# rm32 register map
Vendor: Rainer Meng; Series: RM32; File version: 1
CPU: CM0 r0p0, little endian, MPU, no FPU, 4 interrupt priority bits
Registers are 32-bit, read-write, no defined reset value unless marked. A register's access mark holds for its fields unless they carry their own. Offsets are from the block's base; lines under a group give offsets from that group; [hi:lo] are bit positions; {n}, {i} and the like mark numbered series; 'fields as' and 'values as' point back to an identical list; <NAME> marks a mode.

## Memory map
0x40000000 RCC size 0x3FF — Reset and Clock Controller
0x40010000 UART1 size 0x3FF — Universal Synchronous Receiver Transmitter 1
0x40010400 UART2 size 0x3FF — Universal Synchronous Receiver Transmitter 2
0x40010800 TUART1 size 0x3FF — Test Universal Synchronous Receiver Transmitter 1
0x40020000 FMC size 0x3FF — Flash Memory Controller
0x40080000 GPIOA size 0x3FF — General Purpose Input Output A
0x40080400 GPIOB size 0x3FF — General Purpose Input Output B

## FMC — Flash Memory Controller
Base 0x40020000
0x00 ACR — FMC Access Control Register
  [3:0] LATENCY — FMC ACR LATENCY [3:0] Bits: Access latency
0x04 KEYR wo — FMC Key Register
  [31:0] KEY — FMC KEYR KEY [31:0] Bits: Unlock key
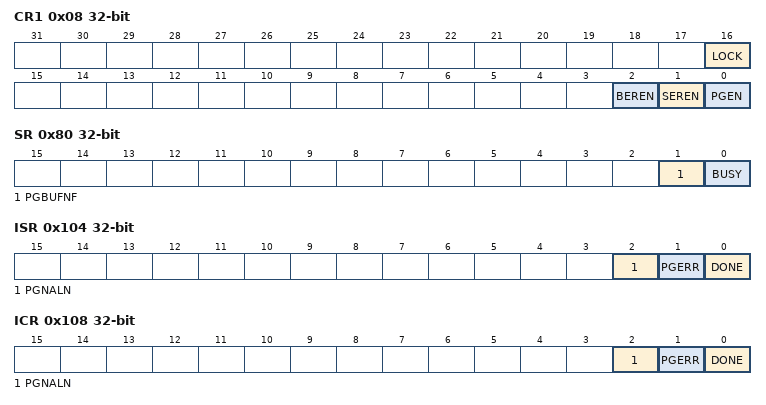
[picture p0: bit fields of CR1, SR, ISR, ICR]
0x08 CR1 — FMC Control Register 1
  [16] LOCK — FMC CR1 LOCK Bit: Lock FMC
  [2] BEREN — FMC CR1 BEREN Bit: Enable / Disable bank erasing
  [1] SEREN — FMC CR1 SEREN Bit: Enable / Disable sector erasing
  [0] PGEN — FMC CR1 PGEN Bit: Enable / Disable programming
0x0C CR2 — FMC Control Register 2
  [0] START — FMC CR2 START Bit: Start erasing
0x40 AR — FMC Address Register
  [31:0] ADDR — FMC AR ADDR [31:0] Bits: Sector erasing address
0x80 SR ro — FMC Status Register
  [1] PGBUFNF — FMC SR PGBUFNF Bit: Programming buf not full
  [0] BUSY — FMC SR BUSY Bit: FMC busy
0x104 ISR ro — FMC Interrupt Status Register
  [2] PGNALN — FMC ISR PGNALN Bit: Programming address not aligned
  [1] PGERR — FMC ISR PGERR Bit: Programming page error
  [0] DONE — FMC ISR DONE Bit: FMC done
0x108 ICR wo — FMC Interrupt Clear Register
  [2] PGNALN — FMC ICR PGNALN Bit: Clear ISR.PGNALN
  [1] PGERR — FMC ICR PGERR Bit: Clear ISR.PGERR
  [0] DONE — FMC ICR DONE Bit: Clear ISR.DONE

## GPIOA — General Purpose Input Output A
Base 0x40080000
Same registers: GPIOB 0x40080400
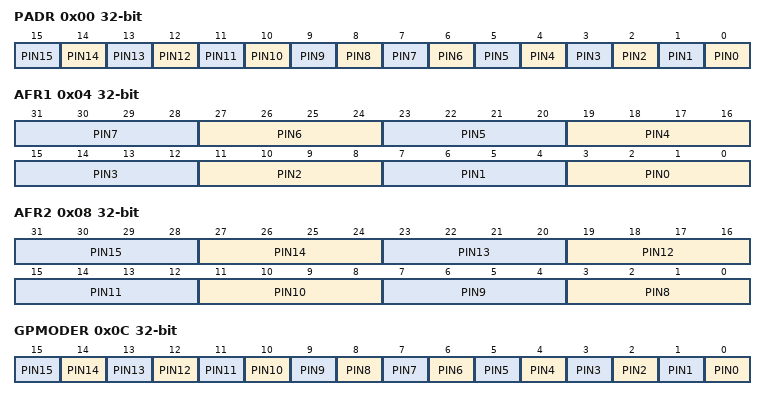
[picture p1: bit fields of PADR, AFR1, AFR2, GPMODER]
0x00 PADR — GPIOA Pad Register
  [n] PIN{n} (n=0..15) — GPIOA PADR PIN{n} Bit: Enable / Disable open drain mode for pin {n}
0x04 AFR1 — GPIOA Alternate Function Register 1
  [4n+3:4n] PIN{n} (n=0..7) — GPIOA AFR1 PIN{n} [3:0] Bits: Alternate function code for pin {n}
0x08 AFR2 — GPIOA Alternate Function Register 2
  [4n-29:4n-32] PIN{n} (n=8..15) — GPIOA AFR2 PIN{n} [3:0] Bits: Alternate function code for pin {n}
0x0C GPMODER — GPIOA Generate Purpose IO Mode Register
  [n] PIN{n} (n=0..15) — GPIOA GPMODER PIN{n} Bit: Select input / output mode for pin {n}
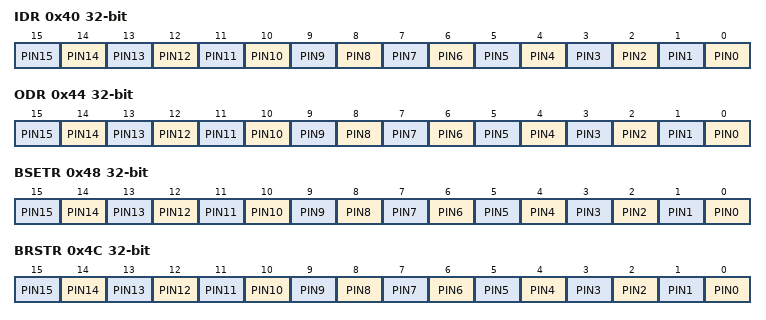
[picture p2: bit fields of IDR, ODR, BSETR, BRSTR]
0x40 IDR ro — GPIOA Input Data Register
  [n] PIN{n} (n=0..15) — GPIOA IDR PIN{n} Bit: Pin {n} input data
0x44 ODR — GPIOA Output Data Register
  [n] PIN{n} (n=0..15) — GPIOA ODR PIN{n} Bit: Pin {n} output data
0x48 BSETR wo — GPIOA Bit Set Register
  [n] PIN{n} (n=0..15) — GPIOA BSETR PIN{n} Bit: Set pin {n}
0x4C BRSTR wo — GPIOA Bit Reset Register
  [n] PIN{n} (n=0..15) — GPIOA BRSTR PIN{n} Bit: Reset pin {n}
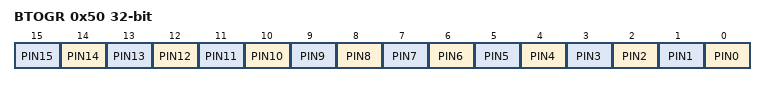
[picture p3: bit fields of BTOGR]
0x50 BTOGR wo — GPIOA Bit Toggle Register
  [n] PIN{n} (n=0..15) — GPIOA BTOGR PIN{n} Bit: Toggle pin {n}

## RCC — Reset and Clock Controller
Base 0x40000000
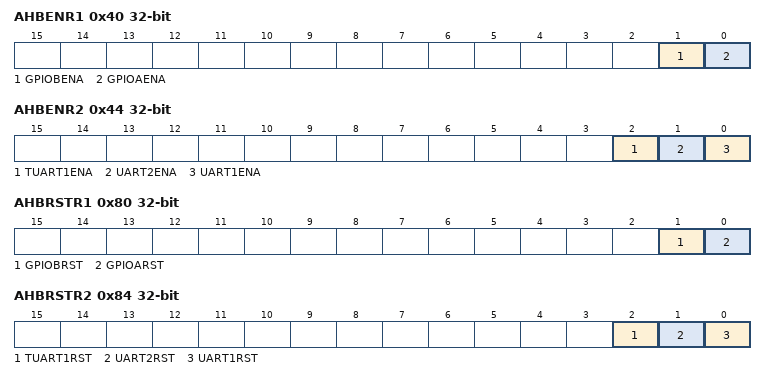
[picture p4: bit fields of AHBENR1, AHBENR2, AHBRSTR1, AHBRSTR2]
0x40 AHBENR1 — RCC AHB Peripheral Enable Register 1
  [1] GPIOBENA — RCC AHBENR1 GPIOBENA Bit: Enable / Disable GPIOB
  [0] GPIOAENA — RCC AHBENR1 GPIOAENA Bit: Enable / Disable GPIOA
0x44 AHBENR2 — RCC AHB Peripheral Enable Register 2
  [2] TUART1ENA — RCC AHBENR2 TUART1ENA Bit: Enable / Disable TUART1
  [1] UART2ENA — RCC AHBENR2 UART2ENA Bit: Enable / Disable UART2
  [0] UART1ENA — RCC AHBENR2 UART1ENA Bit: Enable / Disable UART1
0x80 AHBRSTR1 — RCC AHB Peripheral Reset Register 1
  [1] GPIOBRST — RCC AHBRSTR1 GPIOBRST Bit: Enable / Disable GPIOB
  [0] GPIOARST — RCC AHBRSTR1 GPIOARST Bit: Enable / Disable GPIOA
0x84 AHBRSTR2 — RCC AHB Peripheral Reset Register 2
  [2] TUART1RST — RCC AHBRSTR2 TUART1RST Bit: Enable / Disable TUART1
  [1] UART2RST — RCC AHBRSTR2 UART2RST Bit: Enable / Disable UART2
  [0] UART1RST — RCC AHBRSTR2 UART1RST Bit: Enable / Disable UART1

## TUART1 — Test Universal Synchronous Receiver Transmitter 1
Base 0x40010800
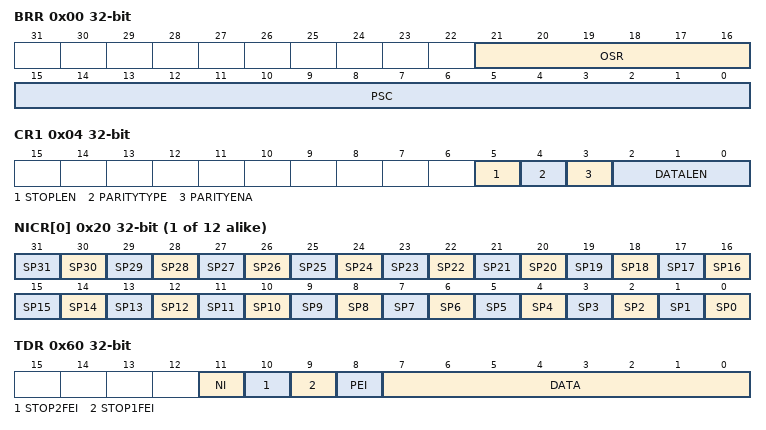
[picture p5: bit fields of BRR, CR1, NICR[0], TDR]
0x00 BRR — TUART1 Baud Rate Register
  [21:16] OSR — TUART1 BRR OSR [5:0] Bits: Oversampling Rate
  [15:0] PSC — TUART1 BRR PSC [15:0] Bits: Prescaler division factor of baud rate generator
0x04 CR1 — TUART1 Control Register 1
  [5] STOPLEN — TUART1 CR1 STOPLEN Bit: Stop bit(s) length
  [4] PARITYTYPE — TUART1 CR1 PARITYTYPE Bit: Parity type
  [3] PARITYENA — TUART1 CR1 PARITYENA Bit: Enable / Disable parity bit
  [2:0] DATALEN — TUART1 CR1 DATALEN [2:0] Bits: Data bit(s) length
0x08 CR2 — TUART1 Control Register 2
  [0] TXENA — TUART1 CR2 TXENA Bit: Enable / Disable TX sub-system
{0x20+4i} NICR[{i}] (i=0..11) — TUART1 Noise Injection Control Register X
  [n] SP{n} (n=0..31) — TUART1 NICR[%s] SP{n} Bit: Noise at sampling point {n}
0x60 TDR — TUART1 TX Data Register
  [11] NI — TUART1 TDR NI Bit: Inject noise
  [10] STOP2FEI — TUART1 TDR STOP2FEI Bit: Inject frame error at stop bit 2
  [9] STOP1FEI — TUART1 TDR STOP1FEI Bit: Inject frame error at stop bit 1
  [8] PEI — TUART1 TDR PEI Bit: Inject parity error
  [7:0] DATA — TUART1 TDR DATA [7:0] Bits: Data
0x80 SR1 ro — TUART1 Status Register 1
  [0] TXRDY — TUART1 SR1 TXRDY Bit: TX data register empty flag

## UART1 — Universal Synchronous Receiver Transmitter 1
Base 0x40010000
Same registers: UART2 0x40010400
Registers as TUART1 (with TUART1 read as UART1).
